# nrf9220_flpr register map
Vendor: Nordic Semiconductor; Series: nRF92; File version: 1
Registers are 32-bit, read-write, reset 0x0 unless marked. A register's access mark holds for its fields unless they carry their own. Offsets are from the block's base; [hi:lo] are bit positions; lines under a group give offsets from that group; {n}, {i} and the like mark numbered series; 'fields as' and 'values as' point back to an identical list.

## VPRCLIC — VPR CLIC registers
Base 0xF0000000
0x00 CLIC group — Unspecified
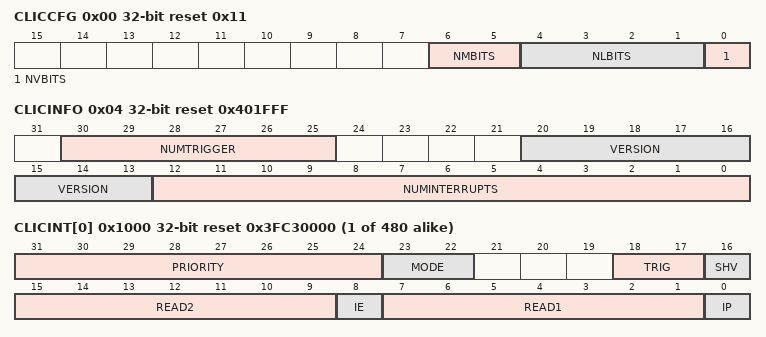
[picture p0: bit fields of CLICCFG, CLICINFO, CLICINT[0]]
  0x00 CLICCFG ro reset 0x11 — CLIC configuration.
    [6:5] NMBITS — Interrupt privilege mode.
      0=ModeM (All interrupts are M-mode only)
    [4:1] NLBITS — Interrupt level encoding.
      8=Eight (8 bits = interrupt levels encoded in eight bits)
    [0] NVBITS — Selective interrupt hardware vectoring.
      1=Implemented (Selective interrupt hardware vectoring is implemented)
  0x04 CLICINFO ro reset 0x401FFF — CLIC information.
    [30:25] NUMTRIGGER — Number of maximum interrupt triggers supported
    [20:13] VERSION
    [12:0] NUMINTERRUPTS — Maximum number of interrupts supported.
  {0x1000+4j} CLICINT[{j}] (j=0..479) reset 0x3FC30000 — Description collection: Interrupt control register for IRQ number [n].
    [31:24] PRIORITY — Interrupt priority level
      63=PRIOLEVEL0 (Priority level 0); 127=PRIOLEVEL1 (Priority level 1); 191=PRIOLEVEL2 (Priority level 2); 255=PRIOLEVEL3 (Priority level 3)
    [23:22] MODE ro — Privilege mode.
      3=MachineMode
    [18:17] TRIG ro — Trigger type and polarity for each interrupt input.
      1=EdgeTriggered (Interrupts are edge-triggered)
    [16] SHV ro — Selective Hardware Vectoring.
      1=Vectored (Hardware vectored)
    [15:9] READ2 ro — Read as 0, write ignored.
    [8] IE — Interrupt enable bit.
      0=Disabled (Interrupt disabled); 1=Enabled (Interrupt enabled)
    [7:1] READ1 ro — Read as 0, write ignored.
    [0] IP — Interrupt Pending bit.
      0=NotPending (Interrupt not pending); 1=Pending (Interrupt pending)

## GLOBAL_MUTEX120 — MUTEX 0
Base 0x4F8D2000
Same registers: GLOBAL_MUTEX130 0x4F927000
{0x400+4i} MUTEX[{i}] (i=0..31) — Description collection: Mutex register
  [0] MUTEX — Mutex register n
    0=Unlocked (Mutex n is in unlocked state); 1=Locked (Mutex n is in locked state)

## GLOBAL_PROTOTYPE — Prototype HW information registers.
Base 0x4F8D2000; alternate view of GLOBAL_MUTEX120
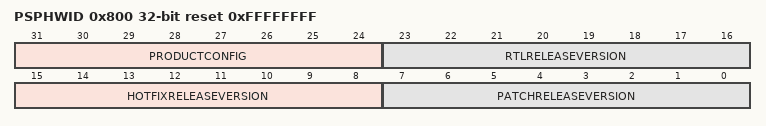
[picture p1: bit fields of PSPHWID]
0x800 PSPHWID ro reset 0xFFFFFFFF — PSP hardware ID register, unique ID for each prototype release. Used to identify RTL release that prototype is based on.
  [31:24] PRODUCTCONFIG
  [23:16] RTLRELEASEVERSION — First letter of RTL release version in ASCII corresponding to A-Z.
  [15:8] HOTFIXRELEASEVERSION
  [7:0] PATCHRELEASEVERSION — PSP patch/bugfix release version
0x804 FPGATIMESTAMP ro — 32-bit timestamp value stored by the FPGA bitstream in format ddddd_MMMM_yyyyyy_hhhhh_mmmmmm_ssssss. Unique for every FPGA netlist implementation, not dependent to RTL synthesis. 0x87654321 set in emulator database.
  [31:0] FPGATIMESTAMP — ddddd = 5 bits to represent 31 days in a month. MMMM = 4 bits to represent 12 months in a year. yyyyyy = 6 bits to represent 0 to 63 (to note year 2000 to 2063). hhhhh = 5 bits to represent 24 hours in a day. mmmmmm = 6 bits to represent 60 minutes in an hour. ssssss = 6 bits to represent 60 seconds in a minute.
0x808 EMULATORSPEEDVALUE ro — Used to store real speed of emulator is running. Used by SW to config UART speed etc, to ensure correct operation.
  [31:0] EMULATORSPEEDVALUE — Actual clock speed for FCLK 400M in emulator (Hz). In FPGA set to 0x0.
0x80C FPGACLOCKDIVIDERRATIO ro — Overall clock divider ratio for FPGA
  [31:0] FPGACLOCKDIVIDERRATIO — Overall clock divider ratio for FPGA. Set to 0 for emulator database.

## GLOBAL_DPPIC120 — Distributed programmable peripheral interconnect controller 0
Base 0x5F8E1000
Same registers: GLOBAL_DPPIC130 0x5F922000, GLOBAL_DPPIC131 0x5F981000, GLOBAL_DPPIC132 0x5F991000, GLOBAL_DPPIC133 0x5F9A1000, GLOBAL_DPPIC134 0x5F9B1000
{0x0+8i} TASKS_CHG[{i}] (i=0..3) group — Channel group tasks
  0x00 EN wo — Description cluster: Enable channel group n
    [0] EN — Enable channel group n
      1=Trigger task
  0x04 DIS wo — Description cluster: Disable channel group n
    [0] DIS — Disable channel group n
      1=Trigger task
{0x80+8i} SUBSCRIBE_CHG[{i}] (i=0..3) group — Subscribe configuration for tasks
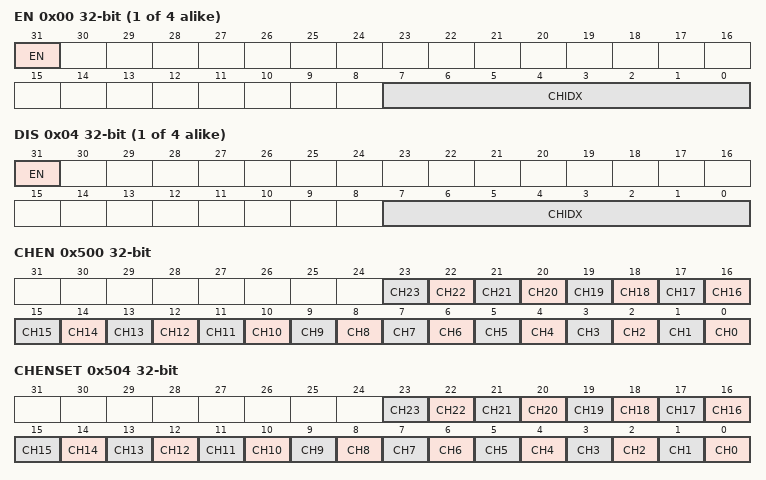
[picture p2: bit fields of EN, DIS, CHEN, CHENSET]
  0x00 EN — Description cluster: Subscribe configuration for task CHG[n].EN
    [31] EN
      0=Disabled (Disable subscription); 1=Enabled (Enable subscription)
    [7:0] CHIDX — DPPI channel that task CHG[n].EN will subscribe to
  0x04 DIS — Description cluster: Subscribe configuration for task CHG[n].DIS
    [31] EN
      values as SUBSCRIBE_CHG[0].EN.EN
    [7:0] CHIDX — DPPI channel that task CHG[n].DIS will subscribe to
0x500 CHEN — Channel enable register
  [all] fields
    0=Disabled (Disable channel); 1=Enabled (Enable channel)
  [n] CH{n} (n=0..23) — Enable or disable channel {n}
0x504 CHENSET write-1-sets — Channel enable set register
  [all] fields
    on read: 0=Disabled (Read: Channel disabled); 1=Enabled (Read: Channel enabled) | on write: 1=Set (Write: Enable channel)
  [n] CH{n} (n=0..23) — Channel {n} enable set register. Writing 0 has no effect.
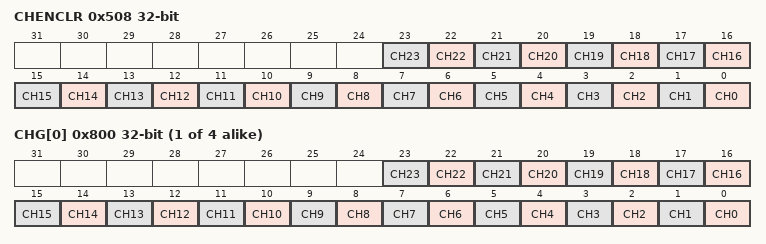
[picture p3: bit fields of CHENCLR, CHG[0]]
0x508 CHENCLR write-1-clears — Channel enable clear register
  [all] fields
    on read: 0=Disabled (Read: Channel disabled); 1=Enabled (Read: Channel enabled) | on write: 1=Clear (Write: Disable channel)
  [n] CH{n} (n=0..23) — Channel {n} enable clear register. Writing 0 has no effect.
{0x800+4i} CHG[{i}] (i=0..3) — Description collection: Channel group n Note: Writes to this register are ignored if either SUBSCRIBE_CHG[n].EN or SUBSCRIBE_CHG[n].DIS is enabled
  [all] fields
    0=Excluded; 1=Included
  [n] CH{n} (n=0..23) — Include or exclude channel {n}
